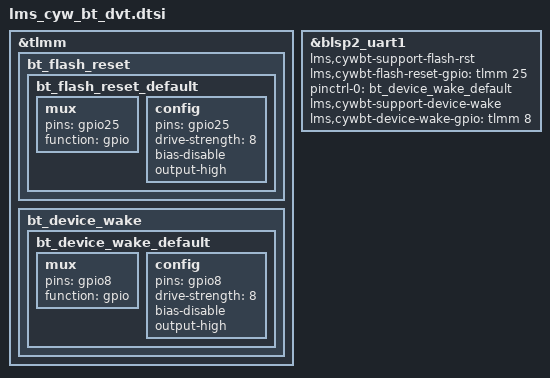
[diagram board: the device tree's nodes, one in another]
&tlmm {
	bt_flash_reset {
		bt_flash_reset_default: bt_flash_reset_default {
			mux {
				pins = "gpio25";
				function = "gpio";
			};
			config {
				pins = "gpio25";
				drive-strength = <8>;
				bias-disable;
				output-high;
			};
		};
	};
    bt_device_wake {
		bt_device_wake_default: bt_device_wake_default {
			mux {
				pins = "gpio8";
				function = "gpio";
			};
			config {
				pins = "gpio8";
				drive-strength = <8>;
				bias-disable;
				output-high;
			};
		};
	};
};


&blsp2_uart1{
        lms,cywbt-support-flash-rst;
        lms,cywbt-flash-reset-gpio = <&tlmm 25 0>;
        pinctrl-0 = <&bt_flash_reset_default>;
    };
&blsp2_uart1{
        lms,cywbt-support-device-wake;
        lms,cywbt-device-wake-gpio = <&tlmm 8 0>;
        pinctrl-0 = <&bt_device_wake_default>;
    };

